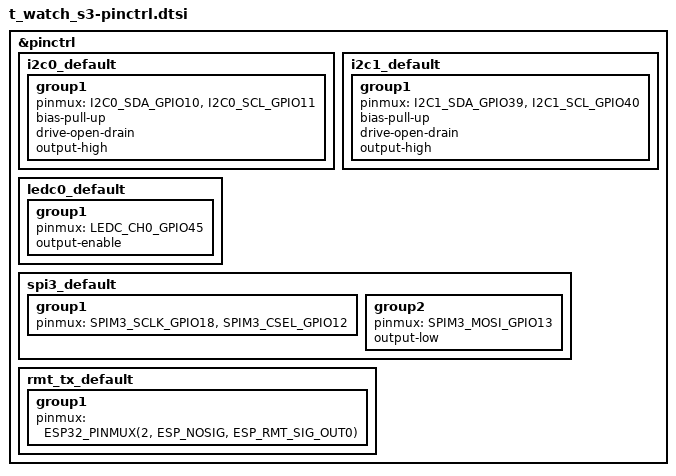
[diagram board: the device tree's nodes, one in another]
/*
 * Copyright (c) 2025 VVVVVVVVVV LLC
 *
 * SPDX-License-Identifier: Apache-2.0
 */

#include <zephyr/dt-bindings/pinctrl/esp-pinctrl-common.h>
#include <zephyr/dt-bindings/pinctrl/esp32s3-pinctrl.h>
#include <zephyr/dt-bindings/pinctrl/esp32s3-gpio-sigmap.h>

&pinctrl {
	i2c0_default: i2c0_default {
		group1 {
			pinmux = <I2C0_SDA_GPIO10>,
					 <I2C0_SCL_GPIO11>;
			bias-pull-up;
			drive-open-drain;
			output-high;
		};
	};

	i2c1_default: i2c1_default {
		group1 {
			pinmux = <I2C1_SDA_GPIO39>,
					 <I2C1_SCL_GPIO40>;
			bias-pull-up;
			drive-open-drain;
			output-high;
		};
	};

	ledc0_default: ledc0_default {
		group1 {
			pinmux = <LEDC_CH0_GPIO45>;
			output-enable;
		};
	};

	spi3_default: spi3_default {
		group1 {
			pinmux = <SPIM3_SCLK_GPIO18>, <SPIM3_CSEL_GPIO12>;
		};
		group2 {
			pinmux = <SPIM3_MOSI_GPIO13>;
			output-low;
		};
	};

	rmt_tx_default: rmt_tx_default {
		group1 {
			pinmux = <ESP32_PINMUX(2, ESP_NOSIG, ESP_RMT_SIG_OUT0)>;
		};
	};
};
